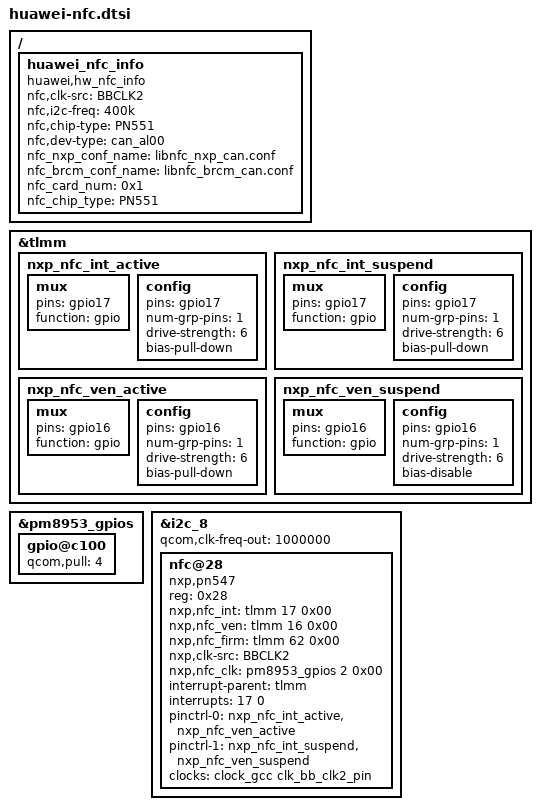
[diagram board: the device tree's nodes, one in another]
/* Copyright (c) 2014-2015, The Linux Foundation. All rights reserved.
 *
 * This program is free software; you can redistribute it and/or modify
 * it under the terms of the GNU General Public License version 2 and
 * only version 2 as published by the Free Software Foundation.
 *
 * This program is distributed in the hope that it will be useful,
 * but WITHOUT ANY WARRANTY; without even the implied warranty of
 * MERCHANTABILITY or FITNESS FOR A PARTICULAR PURPOSE.  See the
 * GNU General Public License for more details.
 */

 / {
	huawei_nfc_info {
		compatible = "huawei,hw_nfc_info";
		nfc,clk-src = "BBCLK2";
		nfc,i2c-freq = "400k";
		nfc,chip-type = "PN551";
		nfc,dev-type = "can_al00";
		nfc_nxp_conf_name = "libnfc_nxp_can.conf";
		nfc_brcm_conf_name = "libnfc_brcm_can.conf";
		nfc_card_num = <0x1>;
		nfc_chip_type = "PN551";
		status = "ok";
	};
};

&tlmm {
	nxp_nfc_int_active: nxp_nfc_int_active{
		mux {
			pins = "gpio17";
			function =  "gpio";
		};
		config {
			pins = "gpio17";
			num-grp-pins = <1>;
			drive-strength = <6>;
			bias-pull-down;
		};
	};
	nxp_nfc_int_suspend: nxp_nfc_int_suspend {
		mux {
			pins = "gpio17";
			function =  "gpio";
		};
		config {
			pins = "gpio17";
			num-grp-pins = <1>;
			drive-strength = <6>;
			bias-pull-down;
		};
	};
	nxp_nfc_ven_active: nxp_nfc_ven_active {
		mux {
			pins = "gpio16";
			function =  "gpio";
		};
		config {
			pins = "gpio16";
			num-grp-pins = <1>;
			drive-strength = <6>;
			bias-pull-down;
		};
	};
	nxp_nfc_ven_suspend: nxp_nfc_ven_suspend {
		mux {
			pins = "gpio16";
			function =  "gpio";
		};
		config {
			pins = "gpio16";
			num-grp-pins = <1>;
			drive-strength = <6>;
			bias-disable;
		};
	};
};

&pm8953_gpios {
	/* GPIO 2 (NFC_CLK_REQ) */
	gpio@c100 {
		qcom,pull = <4>;
		status = "ok";
	};
};

&i2c_8 { /* BLSP2 QUP4 - i2c_8 */
	qcom,clk-freq-out = <1000000>;
	nfc@28 {
		compatible = "nxp,pn547";
		status = "ok";
		reg = <0x28>;
		nxp,nfc_int = <&tlmm 17 0x00>;
		nxp,nfc_ven = <&tlmm 16 0x00>;
		nxp,nfc_firm = <&tlmm 62 0x00>;
		nxp,clk-src = "BBCLK2";
		nxp,nfc_clk = <&pm8953_gpios 2 0x00>;
		interrupt-parent = <&tlmm>;
		interrupts = <17 0>; /*1 = low-to-high edge triggered
					2 = high-to-low edge triggered
					4 = active high level-sensitive
					8 = active low level-sensitive */
		interrupt-names = "nfc_irq";
		pinctrl-names = "nfc_active", "nfc_suspend";
		pinctrl-0 = <&nxp_nfc_int_active &nxp_nfc_ven_active>;
		pinctrl-1 = <&nxp_nfc_int_suspend &nxp_nfc_ven_suspend>;
		clocks = <&clock_gcc clk_bb_clk2_pin>;
		clock-names = "pn547_clk";
	};
};

